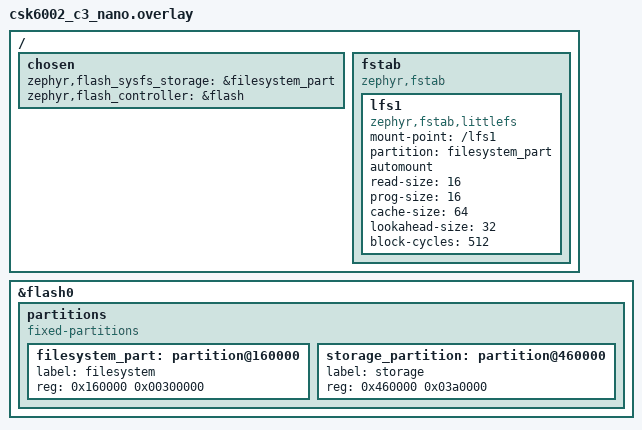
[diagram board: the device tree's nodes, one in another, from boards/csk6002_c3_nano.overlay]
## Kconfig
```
# Copyright (c) 2019-2020 Nordic Semiconductor ASA
# SPDX-License-Identifier: Apache-2.0

DT_CHOSEN_Z_FLASH_SYSFS_STORAGE := zephyr,flash_sysfs_storage
DT_CHOSEN_Z_FLASH_CONTROLLER := zephyr,flash_controller
DT_CHOSEN_Z_INN_FLASH := zephyr,flash



config USB_DEVICE_PID
	default USB_PID_MASS_SAMPLE

config APP_WIPE_STORAGE
	bool "Option to clear the flash area before mounting"
	help
	  Use this to force an existing file system to be created.

choice
	prompt "Storage and file system type used by the application"
	default APP_MSC_STORAGE_NONE
	help
	  Specify the type of storage and file system.

config APP_MSC_STORAGE_NONE
	bool "Use RAM disk as block device"
	imply DISK_DRIVER_RAM

config APP_MSC_STORAGE_RAM
	bool "Use RAM disk and FAT file system"
	imply DISK_DRIVER_RAM
	imply FILE_SYSTEM
	imply FAT_FILESYSTEM_ELM

config APP_MSC_STORAGE_FLASH_FATFS
	bool "Use FLASH disk and FAT file system"
	imply DISK_DRIVER_FLASH
	imply FILE_SYSTEM
	imply FAT_FILESYSTEM_ELM

config APP_MSC_STORAGE_FLASH_LITTLEFS
	bool "Use FLASH disk and LittleFS"
	imply DISK_DRIVER_FLASH
	imply FILE_SYSTEM
	imply FILE_SYSTEM_LITTLEFS

config APP_MSC_STORAGE_SDCARD
	bool "Use SDHC and FAT file system"
	imply DISK_DRIVER_SDMMC
	imply FILE_SYSTEM
	imply FAT_FILESYSTEM_ELM

endchoice

config DISK_RAM_VOLUME_SIZE
	default 32 if APP_MSC_STORAGE_NONE

config MASS_STORAGE_DISK_NAME
	default "NAND" if DISK_DRIVER_FLASH
	default "RAM" if DISK_DRIVER_RAM
	default "SD" if DISK_DRIVER_SDMMC

if DISK_DRIVER_FLASH

config FLASH_MAP
	default y

config FLASH_PAGE_LAYOUT
	default y

config FLASH_LOG_LEVEL
	default 3

	config DISK_FLASH_START
		default "$(dt_chosen_reg_addr_hex,$(DT_CHOSEN_Z_FLASH_SYSFS_STORAGE))"

	config DISK_FLASH_DEV_NAME
		default "$(dt_chosen_label,$(DT_CHOSEN_Z_FLASH_CONTROLLER))"

	config DISK_VOLUME_SIZE
		default "$(dt_chosen_reg_size_hex,$(DT_CHOSEN_Z_FLASH_SYSFS_STORAGE))"


	config DISK_FLASH_MAX_RW_SIZE
		default 4096
		#default $(dt_node_int_prop_hex,$(DT_CHOSEN_Z_INN_FLASH),erase-block-size)

	config DISK_FLASH_ERASE_ALIGNMENT
		default 0x1000
		#default "$(dt_node_int_prop_hex,$(DT_CHOSEN_Z_INN_FLASH),erase-block-size)"

	config DISK_ERASE_BLOCK_SIZE
		default 0x1000
		#default "$(dt_node_int_prop_hex,$(DT_CHOSEN_Z_INN_FLASH),erase-block-size)"
endif
source "Kconfig.zephyr"
```

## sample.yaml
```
sample:
  name: Mass Storage
tests:
  sample.usb.mass_ram_none:
    build_only: true
```

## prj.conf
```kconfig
CONFIG_STDOUT_CONSOLE=y

#USB related configs
CONFIG_USB_DEVICE_STACK=y
CONFIG_USB_DEVICE_PRODUCT="Zephyr MSC sample"
CONFIG_LOG=y
CONFIG_USB_DRIVER_LOG_LEVEL_ERR=y
CONFIG_USB_MASS_STORAGE=y
CONFIG_USB_DEVICE_LOG_LEVEL_ERR=y
CONFIG_USB_MASS_STORAGE_LOG_LEVEL_ERR=y

CONFIG_MAIN_STACK_SIZE=1536
CONFIG_APP_MSC_STORAGE_SDCARD=y
CONFIG_SDMMC_CSK6=y
```

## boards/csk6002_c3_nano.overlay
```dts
/*
 * Copyright (c) 2020 Circuit Dojo LLC
 *
 * SPDX-License-Identifier: Apache-2.0
 */

/delete-node/ &storage_partition;

/ {
	chosen {
		/*
		 * shared memory reserved for the inter-processor communication
		 */
		zephyr,flash_sysfs_storage = &filesystem_part;
		zephyr,flash_controller = &flash;
	};
	
	fstab {
		compatible = "zephyr,fstab";
		lfs1: lfs1 {
			compatible = "zephyr,fstab,littlefs";
			mount-point = "/lfs1";
			partition = <&filesystem_part>;
			automount ;
			read-size = <16>;
			prog-size = <16>;
			cache-size = <64>;
			lookahead-size = <32>;
			block-cycles = <512>;
		};
	};

};

 
&flash0 {
	partitions {
		compatible = "fixed-partitions";
		#address-cells = <1>;
		#size-cells = <1>;
		filesystem_part: partition@160000 {
			label = "filesystem";
			reg = <0x160000 0x00300000>;
		};
		/*
		 * Reserve the final 640 KiB for file system partition
		 */
		storage_partition: partition@460000 {
			label = "storage";
			reg = <0x460000 0x03a0000>;
		};


	};
};
```

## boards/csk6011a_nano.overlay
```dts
/*
 * Copyright (c) 2021 listenai Intelligent Technology (anhui) Co., Ltd.
 *
 * SPDX-License-Identifier: Apache-2.0
 */
/delete-node/ &storage_partition;

/ {
	chosen {
		/*
		 * shared memory reserved for the inter-processor communication
		 */
		zephyr,flash_sysfs_storage = &filesystem_part;
		zephyr,flash_controller = &flash;
	};
	fstab {
		compatible = "zephyr,fstab";
		lfs1: lfs1 {
			compatible = "zephyr,fstab,littlefs";
			mount-point = "/lfs1";
			partition = <&filesystem_part>;
			automount ;
			// no-format;
			read-size = <16>;
			prog-size = <16>;
			cache-size = <64>;
			lookahead-size = <32>;
			block-cycles = <512>;
		};
	};

};


&flash0 {
	partitions {
		compatible = "fixed-partitions";
		#address-cells = <1>;
		#size-cells = <1>;
		filesystem_part: partition@160000 {
			label = "filesystem";
			reg = <0x160000 0x00600000>;
		};
		/*
		 * Reserve the final 640 KiB for file system partition
		 */
		storage_partition: partition@760000 {
			label = "storage";
			reg = <0x760000 0x00a0000>;
		};


	};
};
```

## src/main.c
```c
/*
 * Copyright (c) 2016 Intel Corporation.
 * Copyright (c) 2019-2020 Nordic Semiconductor ASA
 *
 * SPDX-License-Identifier: Apache-2.0
 */

#include <zephyr/zephyr.h>
#include <zephyr/logging/log.h>
#include <zephyr/usb/usb_device.h>
#include <zephyr/fs/fs.h>
#include <stdio.h>

LOG_MODULE_REGISTER(main);

#if CONFIG_DISK_DRIVER_FLASH
#include <zephyr/storage/flash_map.h>
#endif

#if CONFIG_FAT_FILESYSTEM_ELM
#include <ff.h>
#endif

#if CONFIG_FILE_SYSTEM_LITTLEFS
#include <zephyr/fs/littlefs.h>
FS_LITTLEFS_DECLARE_DEFAULT_CONFIG(storage);
#endif

static struct fs_mount_t fs_mnt_flash;
static struct fs_mount_t fs_mnt_ram;
static int setup_flash(struct fs_mount_t *mnt)
{
	int rc = 0;
#if CONFIG_DISK_DRIVER_FLASH
	unsigned int id;
	const struct flash_area *pfa;

	mnt->storage_dev = (void *)FLASH_AREA_ID(filesystem);
	id = (uintptr_t)mnt->storage_dev;

	rc = flash_area_open(id, &pfa);
	printk("Area %u at 0x%x on %s for %u bytes\n",
	       id, (unsigned int)pfa->fa_off, pfa->fa_dev_name,
	       (unsigned int)pfa->fa_size);

	if (rc < 0 && IS_ENABLED(CONFIG_APP_WIPE_STORAGE)) {
		printk("Erasing flash area ... ");
		rc = flash_area_erase(pfa, 0, pfa->fa_size);
		printk("%d\n", rc);
	}

	if (rc < 0) {
		flash_area_close(pfa);
	}
#endif
	return rc;
}

static int mount_app_fs(struct fs_mount_t *mnt)
{
	int rc;

#if CONFIG_FAT_FILESYSTEM_ELM
	static FATFS fat_fs;

	mnt->type = FS_FATFS;
	mnt->fs_data = &fat_fs;

#elif CONFIG_FILE_SYSTEM_LITTLEFS
	mnt->type = FS_LITTLEFS;
	mnt->mnt_point = "/lfs";
	mnt->fs_data = &storage;
#endif
	rc = fs_mount(mnt);

	return rc;
}



static void setup_disk(const char* point)
{
	struct fs_mount_t *mp;
	struct fs_dir_t dir;
	struct fs_statvfs sbuf;
	int rc;

	if(strcmp(point, "/NAND:") == 0){
		mp = &fs_mnt_flash;
		mp->mnt_point = "/NAND:";
		if (IS_ENABLED(CONFIG_DISK_DRIVER_FLASH)) {
			rc = setup_flash(mp);
			if (rc < 0) {
				LOG_ERR("Failed to setup flash area");
				return;
			}
		}
	}
	else if(strcmp(point, "/RAM:") == 0){
		mp = &fs_mnt_ram;
		mp->mnt_point = "/RAM:";
	}
	else
		return;


	if (!IS_ENABLED(CONFIG_FILE_SYSTEM_LITTLEFS) &&
	    !IS_ENABLED(CONFIG_FAT_FILESYSTEM_ELM)) {
		LOG_INF("No file system selected");
		return;
	}

	rc = mount_app_fs(mp);
	if (rc < 0) {
		LOG_ERR("Failed to mount filesystem");
		return;
	}

	/* Allow log messages to flush to avoid interleaved output */
	k_sleep(K_MSEC(50));

	printk("Mount %s: %d\n", mp->mnt_point, rc);

	rc = fs_statvfs(mp->mnt_point, &sbuf);
	if (rc < 0) {
		printk("FAIL: statvfs: %d\n", rc);
		return;
	}

	printk("%s: bsize = %lu ; frsize = %lu ;"
	       " blocks = %lu ; bfree = %lu\n",
	       mp->mnt_point,
	       sbuf.f_bsize, sbuf.f_frsize,
	       sbuf.f_blocks, sbuf.f_bfree);


	fs_dir_t_init(&dir);
	rc = fs_opendir(&dir, mp->mnt_point);
	printk("%s opendir: %d\n", mp->mnt_point, rc);

	if (rc < 0) {
		LOG_ERR("Failed to open directory");
	}

	while (rc >= 0) {
		struct fs_dirent ent = { 0 };

		rc = fs_readdir(&dir, &ent);
		if (rc < 0) {
			LOG_ERR("Failed to read directory entries");
			break;
		}
		if (ent.name[0] == 0) {
			printk("End of files\n");
			break;
		}
		printk("  %c %u %s\n",
		       (ent.type == FS_DIR_ENTRY_FILE) ? 'F' : 'D',
		       ent.size,
		       ent.name);
	}

	(void)fs_closedir(&dir);

	return;
}




void main(void)
{
	int ret;

	setup_disk("/NAND:");
	setup_disk("/RAM:");


	ret = usb_enable(NULL);
	if (ret != 0) {
		LOG_ERR("Failed to enable USB");
		return;
	}

	LOG_INF("The device is put in USB mass storage mode.\n");
}
```
